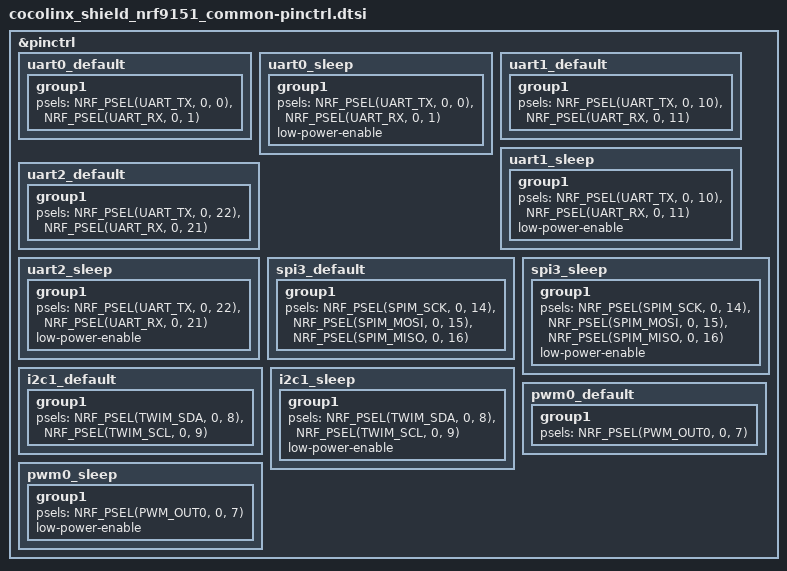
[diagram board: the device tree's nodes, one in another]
/*
 * Copyright (c) 2026 cocolinx
 * SPDX-License-Identifier: Apache-2.0
 */

&pinctrl {
	uart0_default: uart0_default {
		group1 {
			psels = <NRF_PSEL(UART_TX, 0, 0)>,
					<NRF_PSEL(UART_RX, 0, 1)>;
		};
	};
	uart0_sleep: uart0_sleep {
		group1 {
			psels = <NRF_PSEL(UART_TX, 0, 0)>,
					<NRF_PSEL(UART_RX, 0, 1)>;
			low-power-enable;
		};
	};

	uart1_default: uart1_default {
		group1 {
			psels = <NRF_PSEL(UART_TX, 0, 10)>,
					<NRF_PSEL(UART_RX, 0, 11)>;
		};
	};
	uart1_sleep: uart1_sleep {
		group1 {
			psels = <NRF_PSEL(UART_TX, 0, 10)>,
					<NRF_PSEL(UART_RX, 0, 11)>;
			low-power-enable;
		};
	};

	uart2_default: uart2_default {
		group1 {
			psels = <NRF_PSEL(UART_TX, 0, 22)>,
					<NRF_PSEL(UART_RX, 0, 21)>;
		};
	};
	uart2_sleep: uart2_sleep {
		group1 {
			psels = <NRF_PSEL(UART_TX, 0, 22)>,
					<NRF_PSEL(UART_RX, 0, 21)>;
			low-power-enable;
		};
	};

	spi3_default: spi3_default {
		group1 {
			psels = <NRF_PSEL(SPIM_SCK, 0, 14)>,
				<NRF_PSEL(SPIM_MOSI, 0, 15)>,
				<NRF_PSEL(SPIM_MISO, 0, 16)>;
		};
	};

	spi3_sleep: spi3_sleep {
		group1 {
			psels = <NRF_PSEL(SPIM_SCK, 0, 14)>,
				<NRF_PSEL(SPIM_MOSI, 0, 15)>,
				<NRF_PSEL(SPIM_MISO, 0, 16)>;
			low-power-enable;
		};
	};

	i2c1_default: i2c1_default {
		group1 {
			psels = <NRF_PSEL(TWIM_SDA, 0, 8)>,
				<NRF_PSEL(TWIM_SCL, 0, 9)>;
		};
	};

	i2c1_sleep: i2c1_sleep {
		group1 {
			psels = <NRF_PSEL(TWIM_SDA, 0, 8)>,
				<NRF_PSEL(TWIM_SCL, 0, 9)>;
			low-power-enable;
		};
	};

	pwm0_default: pwm0_default {
		group1 {
			psels = <NRF_PSEL(PWM_OUT0, 0, 7)>;
		};
	};

	pwm0_sleep: pwm0_sleep {
		group1 {
			psels = <NRF_PSEL(PWM_OUT0, 0, 7)>;
			low-power-enable;
		};
	};
};
